# globalctrl register map
Vendor: Texas Instruments
Peripheral module from a debugger description file (folder pktdma).
Registers are 32-bit, read-write, no defined reset value unless marked. A register's access mark holds for its fields unless they carry their own. Offsets are as the file gives them; lines under a group give offsets from that group; [hi:lo] are bit positions; {n}, {i} and the like mark numbered series; 'fields as' and 'values as' point back to an identical list; <NAME> marks a mode.

## PKTDMA_GLBCTRL
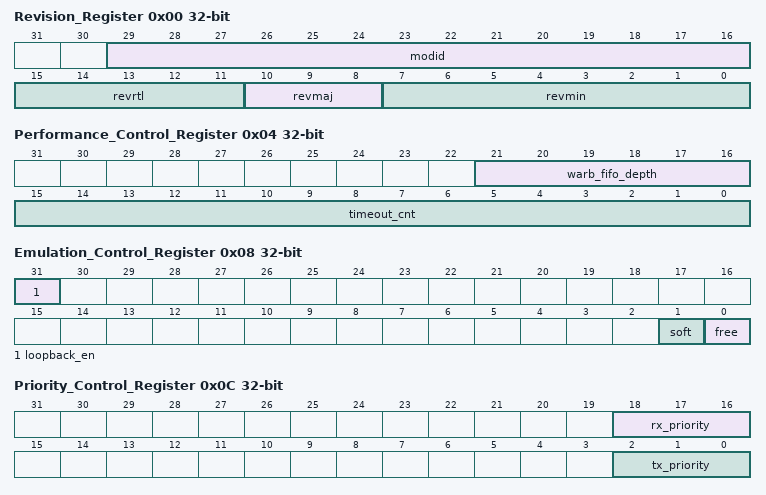
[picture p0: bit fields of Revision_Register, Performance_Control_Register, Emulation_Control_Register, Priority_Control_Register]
0x00 Revision_Register ro — The Revision Register contains the major and minor revisions for the module.
  [29:16] modid — Module ID Field
  [15:11] revrtl — RTL Revision
  [10:8] revmaj — Major Revision
  [7:0] revmin — Minor Revision
0x04 Performance_Control_Register — The performance control register contains fields which can be used to adjust the performance of the CDMAHP in the system.
  [21:16] warb_fifo_depth — Depth of the Write Arbitration FIFO
  [15:0] timeout_cnt — Timeout Duration in Clock Cycles
0x08 Emulation_Control_Register — The emulation control register is used to control the behavior of the DMA when the emususp input is asserted.
  [31] loopback_en — Loopback Enable
  [1] soft
  [0] free
0x0C Priority_Control_Register — The priority control register is used to control the priority of the transactions which the DMA generates on it's master interface.
  [18:16] rx_priority — Receive Priority
  [2:0] tx_priority — Transmit Priority
{0x10+4i} Queue_Manager_{i}_Base_Address_Register (i=0..3) — This register is used to provide a pointer to the base address to the Queues region of Queue Manager {i}.
  [31:0] qm{i}_base
